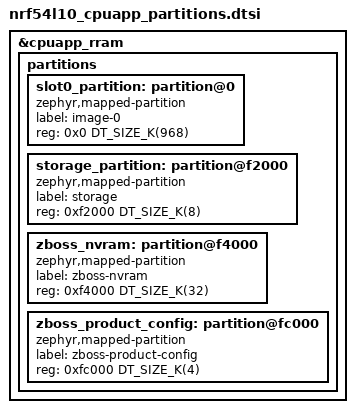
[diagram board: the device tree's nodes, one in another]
/*
 * Copyright (c) 2026 Nordic Semiconductor ASA
 *
 * SPDX-License-Identifier: LicenseRef-Nordic-5-Clause
 */

/delete-node/ &slot0_partition;
/delete-node/ &slot1_partition;
/delete-node/ &storage_partition;

&cpuapp_rram {
	partitions {
		slot0_partition: partition@0 {
			compatible = "zephyr,mapped-partition";
			label = "image-0";
			reg = <0x0 DT_SIZE_K(968)>;
		};

		storage_partition: partition@f2000 {
			compatible = "zephyr,mapped-partition";
			label = "storage";
			reg = <0xf2000 DT_SIZE_K(8)>;
		};

		zboss_nvram: partition@f4000 {
			compatible = "zephyr,mapped-partition";
			label = "zboss-nvram";
			reg = <0xf4000 DT_SIZE_K(32)>;
		};

		zboss_product_config: partition@fc000 {
			compatible = "zephyr,mapped-partition";
			label = "zboss-product-config";
			reg = <0xfc000 DT_SIZE_K(4)>;
		};
	};
};
